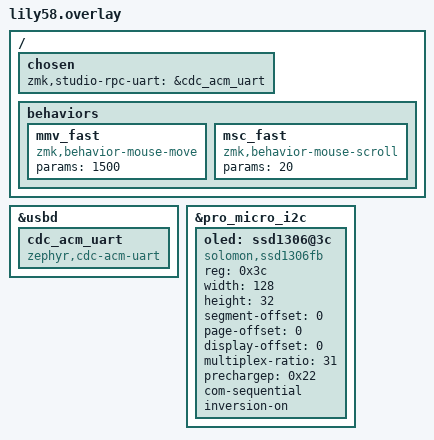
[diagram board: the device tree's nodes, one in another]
/ {
    chosen {
        zmk,studio-rpc-uart = &cdc_acm_uart;
    };
    behaviors {
        mmv_fast: mmv_fast {
            compatible = "zmk,behavior-mouse-move";
            #binding-cells = <1>;
            params = <1500>;   /* cursor speed */
        };
        msc_fast: msc_fast {
            compatible = "zmk,behavior-mouse-scroll";
            #binding-cells = <1>;
            params = <20>;     /* scroll speed */
        };
    };
};

&usbd {
    cdc_acm_uart: cdc_acm_uart {
        compatible = "zephyr,cdc-acm-uart";
    };
};

&pro_micro_i2c {
    status = "okay";
    
    oled: ssd1306@3c {
        compatible = "solomon,ssd1306fb";
        reg = <0x3c>;
        width = <128>;
        height = <32>;
        segment-offset = <0>;
        page-offset = <0>;
        display-offset = <0>;
        multiplex-ratio = <31>;
        prechargep = <0x22>;
        com-sequential;
        inversion-on;
    };
};
```
